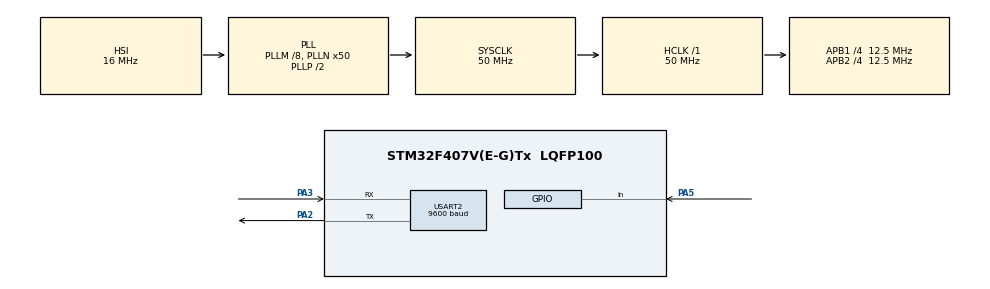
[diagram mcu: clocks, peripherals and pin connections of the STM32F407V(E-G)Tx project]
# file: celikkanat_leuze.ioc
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Mcu.Family=STM32F4
Mcu.Name=STM32F407V(E-G)Tx
Mcu.Package=LQFP100
NVIC.PriorityGroup=NVIC_PRIORITYGROUP_0
NVIC.RTC_WKUP_IRQn=true\:0\:0\:false\:false\:true\:true\:true\:true
PA2.Mode=Asynchronous
PA2.Signal=USART2_TX
PA3.Mode=Asynchronous
PA3.Signal=USART2_RX
PA5.GPIO_PuPd=GPIO_NOPULL
PA5.Signal=GPIO_Input
PH0-OSC_IN.Mode=HSE-External-Oscillator
PH0-OSC_IN.Signal=RCC_OSC_IN
PH1-OSC_OUT.Mode=HSE-External-Oscillator
PH1-OSC_OUT.Signal=RCC_OSC_OUT
ProjectManager.HeapSize=0x200
ProjectManager.StackSize=0x400
ProjectManager.TargetToolchain=STM32CubeIDE
RCC.48MHZClocksFreq_Value=14285714.285714285
RCC.AHBFreq_Value=50000000
RCC.APB1CLKDivider=RCC_HCLK_DIV4
RCC.APB1Freq_Value=12500000
RCC.APB1TimFreq_Value=25000000
RCC.APB2CLKDivider=RCC_HCLK_DIV4
RCC.APB2Freq_Value=12500000
RCC.APB2TimFreq_Value=25000000
RCC.CortexFreq_Value=50000000
RCC.HCLKFreq_Value=50000000
RCC.HSE_VALUE=8000000
RCC.HSI_VALUE=16000000
RCC.LSE_VALUE=32768
RCC.PLLM=8
RCC.PLLN=50
RCC.PLLQ=7
RCC.RCC_RTC_Clock_Source=RCC_RTCCLKSOURCE_LSI
RCC.RCC_RTC_Clock_SourceVirtual=RCC_RTCCLKSOURCE_LSE
RCC.SYSCLKFreq_VALUE=50000000
RCC.SYSCLKSource=RCC_SYSCLKSOURCE_PLLCLK
RCC.VCOOutputFreq_Value=100000000
USART2.BaudRate=9600
USART2.VirtualMode=VM_ASYNC
VP_RTC_VS_RTC_Activate.Mode=RTC_Enabled
VP_RTC_VS_RTC_Calendar.Mode=RTC_Calendar
VP_RTC_VS_RTC_WakeUp_intern.Mode=WakeUp
board=STM32F407G-DISC1

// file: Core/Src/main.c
#include "main.h"

RTC_HandleTypeDef hrtc;
UART_HandleTypeDef huart2;

// Define required variables
bool isRead = true;
int deger1, deger2 = 0;
int sayactop = 0;
int sayac1, sayac2, sayac3, sayac4, sayac5 = 0;
float mesafe1, mesafe2, mesafe3, mesafe4, mesafe5, eskiMesafe = 0;
float mesafetoplam, hiz, hizson = 0;
uint32_t elapsedSeconds, simdikiZaman, degertut, baslangicZamani = 0;
uint32_t sonUcHane, virgulsonrasi, mseconds;

GPIO_InitTypeDef GPIO_InitStruct;

void SystemClock_Config(void);
void Error_Handler(void);
static void MX_GPIO_Init(void);
static void MX_USART2_UART_Init(void);
static void MX_RTC_Init(void);

void HAL_RTCEx_WakeUpTimerEventCallback(RTC_HandleTypeDef *hrtc)
{
	static RTC_TimeTypeDef sTime;

    // Get current time
    HAL_RTC_GetTime(hrtc, &sTime, RTC_FORMAT_BIN);
    mseconds += (sTime.SubSeconds * 1000) / (sTime.SecondFraction + 1);

    elapsedSeconds++;

    sonUcHane = mseconds % 1000;
    baslangicZamani = elapsedSeconds * 1000 + (1000 - sonUcHane);
}

int main(void)
{
  HAL_Init();
  SystemClock_Config();
  MX_GPIO_Init();
  MX_USART2_UART_Init();
  MX_RTC_Init();

  HAL_RTCEx_DeactivateWakeUpTimer(&hrtc); // Deactivate WakeUp Timer

  RTC_TimeTypeDef sTime;

  // Set initial time
  sTime.Hours = 18;
  sTime.Minutes = 50;
  HAL_RTC_SetTime(&hrtc, &sTime, RTC_FORMAT_BIN);

  HAL_RTCEx_SetWakeUpTimer_IT(&hrtc, 2048 - 1, RTC_WAKEUPCLOCK_RTCCLK_DIV16);

	while (1) {

	  deger1 = HAL_GPIO_ReadPin(GPIOA, GPIO_PIN_5);

	  if (mesafe1 < 82) {
		if (deger1 == 1 && isRead) {
		  simdikiZaman = baslangicZamani - degertut;
		  degertut = baslangicZamani;
		  sayac1++;
		  isRead = false;
		}
		else if (deger1 == 0 && mesafe1 != 82) {
		  isRead = true;
		}
		if (sayac1 >= 1) {
		  mesafe1 = 6 + ((sayac1 - 1) * 4);
		  eskiMesafe = 6 + ((sayac1 - 2) * 4);
		  hiz = (mesafe1 - eskiMesafe) / (simdikiZaman);
		}
	  }
/**************************************************************************************************************************/
	  if (mesafe1 >= 82 && mesafe2 < 5.95) {
		mesafe1 = 82;
		if (deger1 == 1 && isRead) {
		  simdikiZaman = baslangicZamani - degertut;
		  degertut = baslangicZamani;
		  sayac2++;
		  isRead = false;
		}
		else if (deger1 == 0 && mesafe2 != 5.95) {
		  isRead = true;
		}
		if (sayac2 >= 1) {
		  mesafe2 = (0.05 * (2 * sayac2 - 1) + 4) ;
		  eskiMesafe = (0.05 * (2 * sayac2 - 2) + 4);
		  hiz = ((mesafe2 - eskiMesafe) / (simdikiZaman))*100;
		}
	  }
/**************************************************************************************************************************/
	  if (mesafe2 >= 5.95 && mesafe3 < 46.05) {
		  mesafe2 = 5.95;
		  if (deger1 == 1 && isRead) {
			  simdikiZaman = baslangicZamani - degertut;
			  degertut = baslangicZamani;
			  sayac3++;
			  isRead = false;
		  }
		  else if (deger1 == 0 && mesafe3 != 46.05) {
			  isRead = true;
		  }
		  if (sayac3 >= 1) {
			  mesafe3 =(2.05 + (sayac3 - 1) * 4) ;
			  eskiMesafe =(2.05 + (sayac3 - 2) * 4) ;
			  hiz = (mesafe3 - eskiMesafe) / (simdikiZaman);
		  }
		}
/*************************************************************************************************************************/
		if (mesafe3 >= 46.05 && mesafe4 < 4.95) {
		  mesafe3 = 46.05;
		  if (deger1 == 1 && isRead) {
			  simdikiZaman = baslangicZamani - degertut;
			  degertut = baslangicZamani;
			  sayac4++;
			  isRead = false;
		  }
		  else if (deger1 == 0 && mesafe4 != 4.95) {
			  isRead = true;
		  }
		  if (sayac4 >= 1) {
			  mesafe4 = (0.05 * (2 * sayac4 - 1)) + 4 ;
			  eskiMesafe = (0.05 * (2 * sayac4 - 2)) + 4 ;
			  hiz = ((mesafe4 - eskiMesafe) / (simdikiZaman))*100;
		  }
		}
/**************************************************************************************************************************/
		if (mesafe4 >= 4.95 && mesafe5 < 47.05) {
		  mesafe4 = 4.95;
		  if (deger1 == 1 && isRead) {
			  simdikiZaman = baslangicZamani - degertut;
			  degertut = baslangicZamani;
			  sayac5++;
			  isRead = false;
		  }
		  else if (deger1 == 0 && mesafe5 != 47.05) {
			  isRead = true;
		  }
		  if (sayac5 >= 1) {
			  mesafe5 =((sayac5 - 1) * 4) + 3.05;
			  eskiMesafe =((sayac5 - 2) * 4) + 3.05;
			  hiz = (mesafe5 - eskiMesafe) / (simdikiZaman);
		  }
		}

		if (mesafe5 >= 47.05) {
		  mesafe5 = 47.05;
		  isRead = false;
		}
/**************************************************************************************************************************/
		mesafetoplam = mesafe1 + mesafe2 + mesafe3 + mesafe4 + mesafe5;
		sayactop = sayac1 + sayac2 + sayac3 + sayac4 + sayac5;
		hizson = hiz * 1000;

		char buffer[100];
		sprintf(buffer, "%.2f\t %.2f\t %lu\n\r", mesafetoplam, hizson, baslangicZamani);
		HAL_UART_Transmit(&huart2, (uint8_t *)buffer, strlen(buffer), HAL_MAX_DELAY);

		HAL_Delay(10); // Adjust delay as needed
		baslangicZamani += 10;
	  }
}

void SystemClock_Config(void)
{
  RCC_OscInitTypeDef RCC_OscInitStruct = {0};
  RCC_ClkInitTypeDef RCC_ClkInitStruct = {0};

  /** Configure the main internal regulator output voltage
  */
  __HAL_RCC_PWR_CLK_ENABLE();
  __HAL_PWR_VOLTAGESCALING_CONFIG(PWR_REGULATOR_VOLTAGE_SCALE1);

  /** Initializes the RCC Oscillators according to the specified parameters
  * in the RCC_OscInitTypeDef structure.
  */
  RCC_OscInitStruct.OscillatorType = RCC_OSCILLATORTYPE_HSI|RCC_OSCILLATORTYPE_LSI;
  RCC_OscInitStruct.HSIState = RCC_HSI_ON;
  RCC_OscInitStruct.HSICalibrationValue = RCC_HSICALIBRATION_DEFAULT;
  RCC_OscInitStruct.LSIState = RCC_LSI_ON;
  RCC_OscInitStruct.PLL.PLLState = RCC_PLL_ON;
  RCC_OscInitStruct.PLL.PLLSource = RCC_PLLSOURCE_HSI;
  RCC_OscInitStruct.PLL.PLLM = 8;
  RCC_OscInitStruct.PLL.PLLN = 50;
  RCC_OscInitStruct.PLL.PLLP = RCC_PLLP_DIV2;
  RCC_OscInitStruct.PLL.PLLQ = 7;
  if (HAL_RCC_OscConfig(&RCC_OscInitStruct) != HAL_OK)
  {
    Error_Handler();
  }

  /** Initializes the CPU, AHB and APB buses clocks
  */
  RCC_ClkInitStruct.ClockType = RCC_CLOCKTYPE_HCLK|RCC_CLOCKTYPE_SYSCLK
                              |RCC_CLOCKTYPE_PCLK1|RCC_CLOCKTYPE_PCLK2;
  RCC_ClkInitStruct.SYSCLKSource = RCC_SYSCLKSOURCE_PLLCLK;
  RCC_ClkInitStruct.AHBCLKDivider = RCC_SYSCLK_DIV1;
  RCC_ClkInitStruct.APB1CLKDivider = RCC_HCLK_DIV4;
  RCC_ClkInitStruct.APB2CLKDivider = RCC_HCLK_DIV4;

  if (HAL_RCC_ClockConfig(&RCC_ClkInitStruct, FLASH_LATENCY_1) != HAL_OK)
  {
    Error_Handler();
  }
}

static void MX_RTC_Init(void)
{

  RTC_TimeTypeDef sTime = {0};
  RTC_DateTypeDef sDate = {0};

  /** Initialize RTC Only
  */
  hrtc.Instance = RTC;
  hrtc.Init.HourFormat = RTC_HOURFORMAT_24;
  hrtc.Init.AsynchPrediv = 127;
  hrtc.Init.SynchPrediv = 255;
  hrtc.Init.OutPut = RTC_OUTPUT_DISABLE;
  hrtc.Init.OutPutPolarity = RTC_OUTPUT_POLARITY_HIGH;
  hrtc.Init.OutPutType = RTC_OUTPUT_TYPE_OPENDRAIN;
  if (HAL_RTC_Init(&hrtc) != HAL_OK)
  {
    Error_Handler();
  }

  /** Initialize RTC and set the Time and Date
  */
  sTime.Hours = 0x0;
  sTime.Minutes = 0x0;
  sTime.Seconds = 0x0;
  sTime.DayLightSaving = RTC_DAYLIGHTSAVING_NONE;
  sTime.StoreOperation = RTC_STOREOPERATION_RESET;
  if (HAL_RTC_SetTime(&hrtc, &sTime, RTC_FORMAT_BCD) != HAL_OK)
  {
    Error_Handler();
  }
  sDate.WeekDay = RTC_WEEKDAY_MONDAY;
  sDate.Month = RTC_MONTH_JANUARY;
  sDate.Date = 0x1;
  sDate.Year = 0x0;

  if (HAL_RTC_SetDate(&hrtc, &sDate, RTC_FORMAT_BCD) != HAL_OK)
  {
    Error_Handler();
  }

  /** Enable the WakeUp
  */
  if (HAL_RTCEx_SetWakeUpTimer_IT(&hrtc, 0, RTC_WAKEUPCLOCK_RTCCLK_DIV16) != HAL_OK)
  {
    Error_Handler();
  }

}

static void MX_USART2_UART_Init(void)
{

  huart2.Instance = USART2;
  huart2.Init.BaudRate = 9600;
  huart2.Init.WordLength = UART_WORDLENGTH_8B;
  huart2.Init.StopBits = UART_STOPBITS_1;
  huart2.Init.Parity = UART_PARITY_NONE;
  huart2.Init.Mode = UART_MODE_TX_RX;
  huart2.Init.HwFlowCtl = UART_HWCONTROL_NONE;
  huart2.Init.OverSampling = UART_OVERSAMPLING_16;
  if (HAL_UART_Init(&huart2) != HAL_OK)
  {
    Error_Handler();
  }

}

static void MX_GPIO_Init(void)
{
  GPIO_InitTypeDef GPIO_InitStruct = {0};

  /* GPIO Ports Clock Enable */
  __HAL_RCC_GPIOH_CLK_ENABLE();
  __HAL_RCC_GPIOA_CLK_ENABLE();

  /*Configure GPIO pin : PA5 */
  GPIO_InitStruct.Pin = GPIO_PIN_5;
  GPIO_InitStruct.Mode = GPIO_MODE_INPUT;
  GPIO_InitStruct.Pull = GPIO_NOPULL;
  HAL_GPIO_Init(GPIOA, &GPIO_InitStruct);

}

void Error_Handler(void)
{
  /* USER CODE BEGIN Error_Handler_Debug */
  /* User can add his own implementation to report the HAL error return state */
  __disable_irq();
  while (1) {
        char error_message[] = "hata\n";
        HAL_UART_Transmit(&huart2, (uint8_t *)error_message, strlen(error_message), HAL_MAX_DELAY);
        HAL_Delay(1000); // Adjust delay as needed
      }
  /* USER CODE END Error_Handler_Debug */
}
